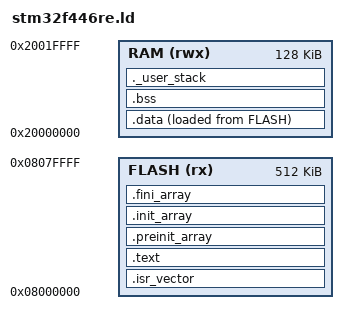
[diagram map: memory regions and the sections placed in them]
/* STM32F446RE: 512 KiB flash, 128 KiB contiguous SRAM. MSP grows down from
 * _estack. FreeRTOS task stacks live in .bss. The reserved tail is the
 * minimum left for interrupt and startup use of the main stack. */
ENTRY(Reset_Handler)

_Min_Stack_Size = 0x1000;
_estack = ORIGIN(RAM) + LENGTH(RAM);

MEMORY
{
  FLASH (rx) : ORIGIN = 0x08000000, LENGTH = 512K
  RAM (rwx)  : ORIGIN = 0x20000000, LENGTH = 128K
}

SECTIONS
{
  .isr_vector :
  {
    . = ALIGN(4);
    KEEP(*(.isr_vector))
  } > FLASH

  .text :
  {
    . = ALIGN(4);
    *(.text*)
    *(.rodata*)
    . = ALIGN(4);
    _etext = .;
  } > FLASH

  .preinit_array :
  {
    . = ALIGN(4);
    PROVIDE_HIDDEN(__preinit_array_start = .);
    KEEP(*(.preinit_array*))
    PROVIDE_HIDDEN(__preinit_array_end = .);
  } > FLASH

  .init_array :
  {
    . = ALIGN(4);
    PROVIDE_HIDDEN(__init_array_start = .);
    KEEP(*(SORT(.init_array.*)))
    KEEP(*(.init_array*))
    PROVIDE_HIDDEN(__init_array_end = .);
  } > FLASH

  .fini_array :
  {
    . = ALIGN(4);
    PROVIDE_HIDDEN(__fini_array_start = .);
    KEEP(*(SORT(.fini_array.*)))
    KEEP(*(.fini_array*))
    PROVIDE_HIDDEN(__fini_array_end = .);
  } > FLASH

  _sidata = LOADADDR(.data);

  .data :
  {
    . = ALIGN(8);
    _sdata = .;
    *(.data*)
    . = ALIGN(8);
    _edata = .;
  } > RAM AT > FLASH

  .bss (NOLOAD) :
  {
    . = ALIGN(8);
    _sbss = .;
    *(.bss*)
    *(COMMON)
    . = ALIGN(8);
    _ebss = .;
  } > RAM

  ._user_stack (NOLOAD) :
  {
    . = ALIGN(8);
    . = . + _Min_Stack_Size;
  } > RAM

  . = ALIGN(8);
  _end = .;
  PROVIDE(end = .);

  ASSERT(_ebss + _Min_Stack_Size <= ORIGIN(RAM) + LENGTH(RAM), "RAM overflow")

  /DISCARD/ :
  {
    *(.ARM.exidx*)
    *(.ARM.extab*)
  }
}
